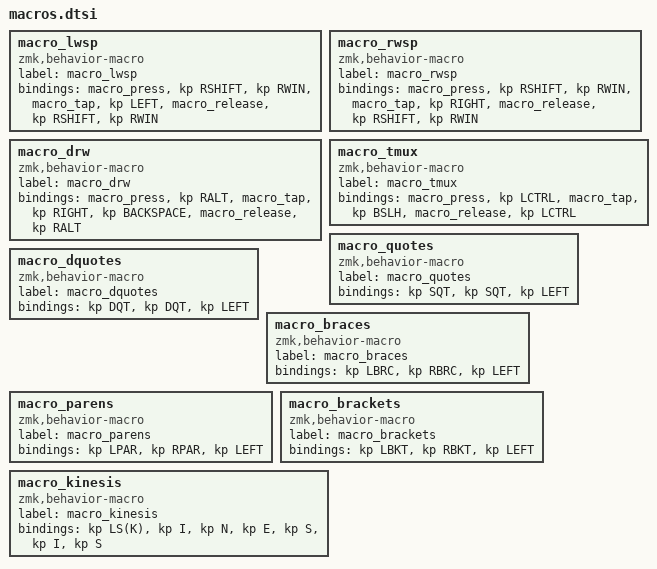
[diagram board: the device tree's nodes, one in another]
// kp-c: move to the left workspace
macro_lwsp: macro_lwsp {
    label = "macro_lwsp";
    compatible = "zmk,behavior-macro";
    #binding-cells = <0>;
    bindings = <&macro_press &kp RSHIFT &kp RWIN>, <&macro_tap &kp LEFT>, <&macro_release &kp RSHIFT &kp RWIN>;
};

// kp-v: move to the right workspace
macro_rwsp: macro_rwsp {
    label = "macro_rwsp";
    compatible = "zmk,behavior-macro";
    #binding-cells = <0>;
    bindings = <&macro_press &kp RSHIFT &kp RWIN>, <&macro_tap &kp RIGHT>, <&macro_release &kp RSHIFT &kp RWIN>;
};

// kp-d: delete the word to the right
macro_drw: macro_drw {
    label = "macro_drw";
    compatible = "zmk,behavior-macro";
    #binding-cells = <0>;
    bindings = <&macro_press &kp RALT>, <&macro_tap &kp RIGHT &kp BACKSPACE>, <&macro_release &kp RALT>;
};

// F5: tmux leading key
macro_tmux: macro_tmux {
    label = "macro_tmux";
    compatible = "zmk,behavior-macro";
    #binding-cells = <0>;
    bindings = <&macro_press &kp LCTRL>, <&macro_tap &kp BSLH>, <&macro_release &kp LCTRL>;
};

macro_quotes: macro_quotes{
compatible = "zmk,behavior-macro";
label = "macro_quotes";
#binding-cells = <0>;
bindings = <&kp SQT>, <&kp SQT>, <&kp LEFT>;
};
macro_dquotes: macro_dquotes{
compatible = "zmk,behavior-macro";
label = "macro_dquotes";
#binding-cells = <0>;
bindings = <&kp DQT>, <&kp DQT>, <&kp LEFT>;
};
macro_braces: macro_braces{
compatible = "zmk,behavior-macro";
label = "macro_braces";
#binding-cells = <0>;
bindings = <&kp LBRC>, <&kp RBRC>, <&kp LEFT>;
};
macro_parens: macro_parens{
compatible = "zmk,behavior-macro";
label = "macro_parens";
#binding-cells = <0>;
bindings = <&kp LPAR>, <&kp RPAR>, <&kp LEFT>;
};
macro_brackets: macro_brackets{
compatible = "zmk,behavior-macro";
label = "macro_brackets";
#binding-cells = <0>;
bindings = <&kp LBKT>, <&kp RBKT>, <&kp LEFT>;
};
macro_kinesis: macro_kinesis{
compatible = "zmk,behavior-macro";
label = "macro_kinesis";
#binding-cells = <0>;
bindings = <&kp LS(K)>, <&kp I>, <&kp N>, <&kp E>, <&kp S>, <&kp I>, <&kp S>;
};
